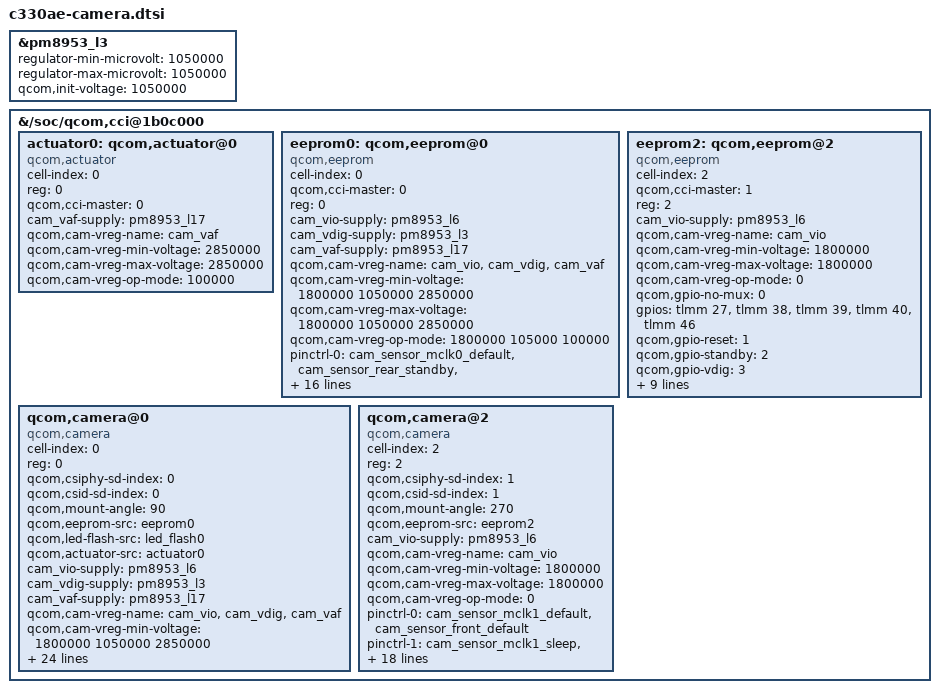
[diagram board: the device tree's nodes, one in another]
/* C330AE camera wiring: rear + front sensors and their EEPROM/actuator. */

#include <dt-bindings/clock/msm-clocks-8952.h>

&pm8953_l3 {
	regulator-min-microvolt = <1050000>;
	regulator-max-microvolt = <1050000>;
	qcom,init-voltage = <1050000>;
};

&{/soc/qcom,cci@1b0c000} {
	actuator0: qcom,actuator@0 {
		cell-index = <0>;
		reg = <0>;
		compatible = "qcom,actuator";
		qcom,cci-master = <0>;
		cam_vaf-supply = <&pm8953_l17>;
		qcom,cam-vreg-name = "cam_vaf";
		qcom,cam-vreg-min-voltage = <2850000>;
		qcom,cam-vreg-max-voltage = <2850000>;
		qcom,cam-vreg-op-mode = <100000>;
	};

	eeprom0: qcom,eeprom@0 {
		cell-index = <0>;
		compatible = "qcom,eeprom";
		qcom,cci-master = <0>;
		reg = <0>;
		cam_vio-supply = <&pm8953_l6>;
		cam_vdig-supply = <&pm8953_l3>;
		cam_vaf-supply = <&pm8953_l17>;
		qcom,cam-vreg-name = "cam_vio", "cam_vdig", "cam_vaf";
		qcom,cam-vreg-min-voltage = <1800000 1050000 2850000>;
		qcom,cam-vreg-max-voltage = <1800000 1050000 2850000>;
		qcom,cam-vreg-op-mode = <1800000 105000 100000>;
		pinctrl-names = "cam_default", "cam_suspend";
		pinctrl-0 = <&cam_sensor_mclk0_default
			&cam_sensor_rear_standby
			&cam_sensor_rear_reset
			&cam_sensor_rear_vana>;
		pinctrl-1 = <&cam_sensor_mclk0_sleep
			&cam_sensor_rear_standby_sleep
			&cam_sensor_rear_reset_sleep
			&cam_sensor_rear_vana_sleep>;
		gpios = <&tlmm 26 0>,
			<&tlmm 132 0>,
			<&tlmm 48 0>,
			<&tlmm 46 0>;
		qcom,gpio-standby = <1>;
		qcom,gpio-reset = <2>;
		qcom,gpio-vana = <3>;
		qcom,gpio-req-tbl-num = <0 1 2 3>;
		qcom,gpio-req-tbl-flags = <1 0 0 0>;
		qcom,gpio-req-tbl-label = "CAMIF_MCLK0",
			"CAM_STANDBY0",
			"CAM_RESET0",
			"CAM_VANA";
		status = "ok";
		clocks = <&clock_gcc clk_mclk0_clk_src>,
			<&clock_gcc clk_gcc_camss_mclk0_clk>;
		clock-names = "cam_src_clk", "cam_clk";
		qcom,clock-rates = <24000000 0>;
	};

	eeprom2: qcom,eeprom@2 {
		cell-index = <2>;
		compatible = "qcom,eeprom";
		qcom,cci-master = <1>;
		reg = <2>;
		cam_vio-supply = <&pm8953_l6>;
		qcom,cam-vreg-name = "cam_vio";
		qcom,cam-vreg-min-voltage = <1800000>;
		qcom,cam-vreg-max-voltage = <1800000>;
		qcom,cam-vreg-op-mode = <0>;
		qcom,gpio-no-mux = <0>;
		gpios = <&tlmm 27 0>,
			<&tlmm 38 0>,
			<&tlmm 39 0>,
			<&tlmm 40 0>,
			<&tlmm 46 0>;
		qcom,gpio-reset = <1>;
		qcom,gpio-standby = <2>;
		qcom,gpio-vdig = <3>;
		qcom,gpio-vana = <4>;
		qcom,gpio-req-tbl-num = <0 1 2 3 4>;
		qcom,gpio-req-tbl-flags = <1 0 0 0 0>;
		qcom,gpio-req-tbl-label = "CAMIF_MCLK2",
			"CAM_RESET2",
			"CAM_STANDBY2",
			"CAM_VDIG2",
			"CAM_VANA2";
		status = "ok";
		clocks = <&clock_gcc clk_mclk1_clk_src>,
			<&clock_gcc clk_gcc_camss_mclk1_clk>;
		clock-names = "cam_src_clk", "cam_clk";
		qcom,clock-rates = <24000000 0>;
	};

	qcom,camera@0 {
		cell-index = <0>;
		compatible = "qcom,camera";
		reg = <0>;
		qcom,csiphy-sd-index = <0>;
		qcom,csid-sd-index = <0>;
		qcom,mount-angle = <90>;
		qcom,eeprom-src = <&eeprom0>;
		qcom,led-flash-src = <&led_flash0>;
		qcom,actuator-src = <&actuator0>;
		cam_vio-supply = <&pm8953_l6>;
		cam_vdig-supply = <&pm8953_l3>;
		cam_vaf-supply = <&pm8953_l17>;
		qcom,cam-vreg-name = "cam_vio", "cam_vdig", "cam_vaf";
		qcom,cam-vreg-min-voltage = <1800000 1050000 2850000>;
		qcom,cam-vreg-max-voltage = <1800000 1050000 2850000>;
		qcom,cam-vreg-op-mode = <1800000 105000 100000>;
		pinctrl-names = "cam_default", "cam_suspend";
		pinctrl-0 = <&cam_sensor_mclk0_default
			&cam_sensor_rear_standby
			&cam_sensor_rear_reset
			&cam_sensor_rear_vana>;
		pinctrl-1 = <&cam_sensor_mclk0_sleep
			&cam_sensor_rear_standby_sleep
			&cam_sensor_rear_reset_sleep
			&cam_sensor_rear_vana_sleep>;
		gpios = <&tlmm 26 0>,
				<&tlmm 132 0>,
				<&tlmm 48 0>,
				<&tlmm 46 0>;
		qcom,gpio-standby = <1>;
		qcom,gpio-reset = <2>;
		qcom,gpio-vana = <3>;
		qcom,gpio-req-tbl-num = <0 1 2 3>;
		qcom,gpio-req-tbl-flags = <1 0 0 0>;
		qcom,gpio-req-tbl-label = "CAMIF_MCLK0",
			"CAM_STANDBY0",
			"CAM_RESET0",
			"CAM_VANA";
		qcom,sensor-position = <0>;
		qcom,sensor-mode = <0>;
		qcom,cci-master = <0>;
		status = "ok";
		clocks = <&clock_gcc clk_mclk0_clk_src>,
				 <&clock_gcc clk_gcc_camss_mclk0_clk>;
		clock-names = "cam_src_clk", "cam_clk";
		qcom,clock-rates = <24000000 0>;
	};

	qcom,camera@2 {
		cell-index = <2>;
		compatible = "qcom,camera";
		reg = <2>;
		qcom,csiphy-sd-index = <1>;
		qcom,csid-sd-index = <1>;
		qcom,mount-angle = <270>;
		qcom,eeprom-src = <&eeprom2>;
		cam_vio-supply = <&pm8953_l6>;
		qcom,cam-vreg-name = "cam_vio";
		qcom,cam-vreg-min-voltage = <1800000>;
		qcom,cam-vreg-max-voltage = <1800000>;
		qcom,cam-vreg-op-mode = <0>;
		pinctrl-names = "cam_default", "cam_suspend";
pinctrl-0 = <&cam_sensor_mclk1_default
        &cam_sensor_front_default>;
pinctrl-1 = <&cam_sensor_mclk1_sleep
        &cam_sensor_front_sleep>;
		gpios = <&tlmm 27 0>,
			<&tlmm 38 0>,
			<&tlmm 39 0>,
			<&tlmm 40 0>,
			<&tlmm 46 0>;
		qcom,gpio-reset = <1>;
		qcom,gpio-standby = <2>;
		qcom,gpio-vdig = <3>;
		qcom,gpio-vana = <4>;
		qcom,gpio-req-tbl-num = <0 1 2 3 4>;
		qcom,gpio-req-tbl-flags = <1 0 0 0 0>;
		qcom,gpio-req-tbl-label = "CAMIF_MCLK2",
			"CAM_RESET2",
			"CAM_STANDBY2",
			"CAM_VDIG2",
			"CAM_VANA2";
		qcom,sensor-position = <1>;
		qcom,sensor-mode = <0>;
		qcom,cci-master = <1>;
		clocks = <&clock_gcc clk_mclk1_clk_src>,
			<&clock_gcc clk_gcc_camss_mclk1_clk>;
		clock-names = "cam_src_clk", "cam_clk";
		qcom,clock-rates = <24000000 0>;
	};
};
